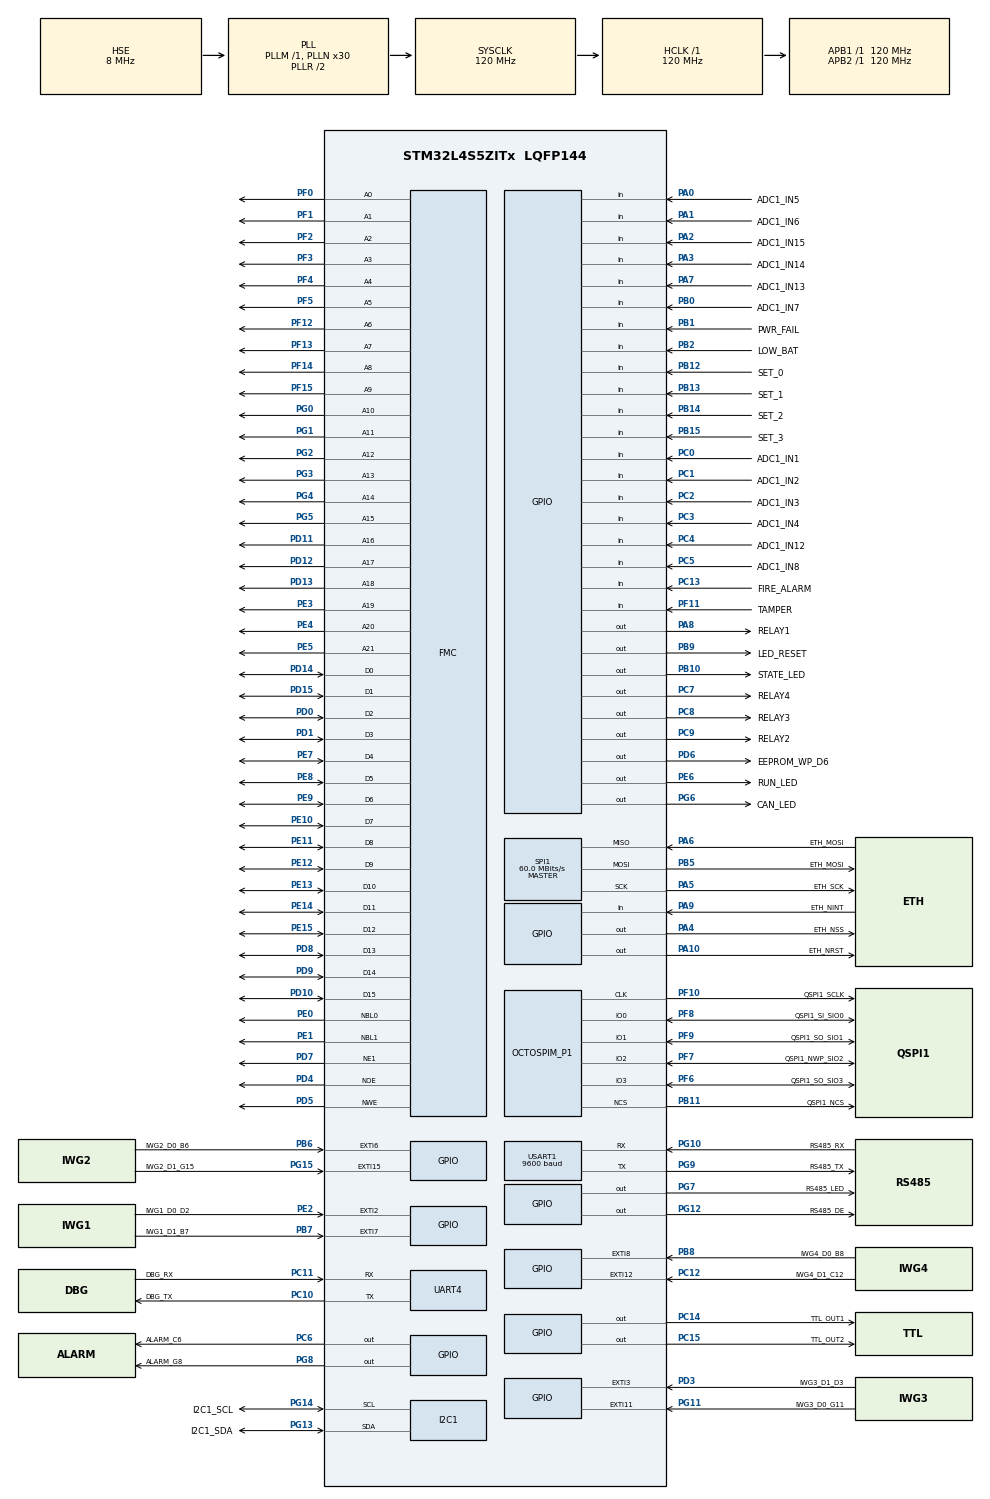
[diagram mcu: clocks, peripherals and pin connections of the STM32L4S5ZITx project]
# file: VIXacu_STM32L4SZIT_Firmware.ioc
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CRC.DefaultInitValueUse=DEFAULT_INIT_VALUE_ENABLE
CRC.DefaultPolynomialUse=DEFAULT_POLYNOMIAL_ENABLE
CRC.InputDataFormat=CRC_INPUTDATA_FORMAT_WORDS
Dma.Request0=SPI1_TX
Dma.Request1=SPI1_RX
Dma.SPI1_RX.1.Direction=DMA_PERIPH_TO_MEMORY
Dma.SPI1_RX.1.EventEnable=DISABLE
Dma.SPI1_RX.1.Instance=DMA1_Channel1
Dma.SPI1_RX.1.MemDataAlignment=DMA_MDATAALIGN_BYTE
Dma.SPI1_RX.1.MemInc=DMA_MINC_ENABLE
Dma.SPI1_RX.1.Mode=DMA_NORMAL
Dma.SPI1_RX.1.PeriphDataAlignment=DMA_PDATAALIGN_BYTE
Dma.SPI1_RX.1.PeriphInc=DMA_PINC_DISABLE
Dma.SPI1_RX.1.Polarity=HAL_DMAMUX_REQUEST_GEN_RISING
Dma.SPI1_RX.1.Priority=DMA_PRIORITY_LOW
Dma.SPI1_RX.1.RequestNumber=1
Dma.SPI1_RX.1.SignalID=NONE
Dma.SPI1_RX.1.SyncEnable=DISABLE
Dma.SPI1_RX.1.SyncPolarity=HAL_DMAMUX_SYNC_NO_EVENT
Dma.SPI1_RX.1.SyncRequestNumber=1
Dma.SPI1_RX.1.SyncSignalID=NONE
Dma.SPI1_TX.0.Direction=DMA_MEMORY_TO_PERIPH
Dma.SPI1_TX.0.EventEnable=DISABLE
Dma.SPI1_TX.0.Instance=DMA1_Channel3
Dma.SPI1_TX.0.MemDataAlignment=DMA_MDATAALIGN_BYTE
Dma.SPI1_TX.0.MemInc=DMA_MINC_ENABLE
Dma.SPI1_TX.0.Mode=DMA_NORMAL
Dma.SPI1_TX.0.PeriphDataAlignment=DMA_PDATAALIGN_BYTE
Dma.SPI1_TX.0.PeriphInc=DMA_PINC_DISABLE
Dma.SPI1_TX.0.Polarity=HAL_DMAMUX_REQUEST_GEN_RISING
Dma.SPI1_TX.0.Priority=DMA_PRIORITY_LOW
Dma.SPI1_TX.0.RequestNumber=1
Dma.SPI1_TX.0.SignalID=NONE
Dma.SPI1_TX.0.SyncEnable=DISABLE
Dma.SPI1_TX.0.SyncPolarity=HAL_DMAMUX_SYNC_NO_EVENT
Dma.SPI1_TX.0.SyncRequestNumber=1
Dma.SPI1_TX.0.SyncSignalID=NONE
HASH.SecureHashAlgorithmType=SHA256
I2C1.Timing=0x30A175AB
IWDG.Prescaler=IWDG_PRESCALER_256
Mcu.Family=STM32L4
Mcu.Name=STM32L4S5ZITx
Mcu.Package=LQFP144
NVIC.DMA1_Channel1_IRQn=true\:0\:0\:false\:false\:true\:false\:true\:true
NVIC.DMA1_Channel3_IRQn=true\:0\:0\:false\:false\:true\:false\:true\:true
NVIC.EXTI15_10_IRQn=true\:0\:0\:false\:false\:true\:true\:true\:true
NVIC.EXTI2_IRQn=true\:0\:0\:false\:false\:true\:true\:true\:true
NVIC.EXTI3_IRQn=true\:0\:0\:false\:false\:true\:true\:true\:true
NVIC.EXTI9_5_IRQn=true\:0\:0\:false\:false\:true\:true\:true\:true
NVIC.HASH_CRS_IRQn=true\:0\:0\:false\:false\:true\:true\:true\:true
NVIC.I2C1_ER_IRQn=true\:0\:0\:false\:false\:true\:true\:true\:true
NVIC.OCTOSPI1_IRQn=true\:0\:0\:false\:false\:true\:true\:true\:true
NVIC.PriorityGroup=NVIC_PRIORITYGROUP_4
NVIC.RNG_IRQn=true\:0\:0\:false\:false\:true\:true\:true\:true
NVIC.SPI1_IRQn=true\:0\:0\:false\:false\:true\:true\:true\:true
NVIC.TIM1_CC_IRQn=true\:0\:0\:false\:false\:true\:true\:true\:true
NVIC.TIM1_UP_TIM16_IRQn=true\:0\:0\:false\:false\:true\:true\:true\:true
NVIC.TIM2_IRQn=true\:0\:0\:false\:false\:true\:true\:true\:true
NVIC.TIM3_IRQn=true\:0\:0\:false\:false\:true\:true\:true\:true
NVIC.TIM4_IRQn=true\:0\:0\:false\:false\:true\:true\:true\:true
NVIC.TIM5_IRQn=true\:0\:0\:false\:false\:true\:true\:true\:true
NVIC.TIM6_DAC_IRQn=true\:15\:0\:false\:false\:true\:true\:true\:true
NVIC.TIM7_IRQn=true\:0\:0\:false\:false\:true\:true\:true\:true
NVIC.UART4_IRQn=true\:15\:0\:true\:false\:true\:true\:true\:true
NVIC.USART1_IRQn=true\:5\:0\:true\:false\:true\:true\:true\:true
OCTOSPI1.ChipSelectHighTime=2
OCTOSPI1.ClockPrescaler=2
OCTOSPI1.DelayBlockBypass=HAL_OSPI_DELAY_BLOCK_BYPASSED
OCTOSPI1.DelayHoldQuarterCycle=HAL_OSPI_DHQC_DISABLE
OCTOSPI1.DeviceSize=26
OCTOSPI1.FifoThreshold=4
OCTOSPI1.MemoryType=HAL_OSPI_MEMTYPE_MACRONIX
OCTOSPI1.SampleShifting=HAL_OSPI_SAMPLE_SHIFTING_HALFCYCLE
PA0.GPIO_Label=ADC1_IN5
PA0.Signal=GPIO_Input
PA1.GPIO_Label=ADC1_IN6
PA1.Signal=GPIO_Input
PA10.GPIO_Label=ETH_NRST
PA10.PinState=GPIO_PIN_SET
PA10.Signal=GPIO_Output
PA13\ (JTMS/SWDIO).Mode=Trace_Asynchronous_SW
PA13\ (JTMS/SWDIO).Signal=SYS_JTMS-SWDIO
PA14\ (JTCK/SWCLK).Mode=Trace_Asynchronous_SW
PA14\ (JTCK/SWCLK).Signal=SYS_JTCK-SWCLK
PA2.GPIO_Label=ADC1_IN15
PA2.Signal=GPIO_Input
PA3.GPIO_Label=ADC1_IN14
PA3.Signal=GPIO_Input
PA4.GPIO_Label=ETH_NSS
PA4.Signal=GPIO_Output
PA5.GPIO_Label=ETH_SCK
PA5.Mode=Full_Duplex_Master
PA5.Signal=SPI1_SCK
PA6.GPIO_Label=ETH_MOSI
PA6.Mode=Full_Duplex_Master
PA6.Signal=SPI1_MISO
PA7.GPIO_Label=ADC1_IN13
PA7.Signal=GPIO_Input
PA8.GPIO_Label=RELAY1
PA8.Signal=GPIO_Output
PA9.GPIO_Label=ETH_NINT
PA9.GPIO_PuPd=GPIO_PULLUP
PA9.Signal=GPIO_Input
PB0.GPIO_Label=ADC1_IN7
PB0.Signal=GPIO_Input
PB1.GPIO_Label=PWR_FAIL
PB1.Signal=GPIO_Input
PB10.GPIO_Label=STATE_LED
PB10.Signal=GPIO_Output
PB11.GPIO_Label=QSPI1_NCS
PB11.Mode=OCTOSPI1_Port1_NCS
PB11.Signal=OCTOSPIM_P1_NCS
PB12.GPIO_Label=SET_0
PB12.Signal=GPIO_Input
PB13.GPIO_Label=SET_1
PB13.Signal=GPIO_Input
PB14.GPIO_Label=SET_2
PB14.Signal=GPIO_Input
PB15.GPIO_Label=SET_3
PB15.Signal=GPIO_Input
PB2.GPIO_Label=LOW_BAT
PB2.Signal=GPIO_Input
PB3\ (JTDO/TRACESWO).Mode=Trace_Asynchronous_SW
PB3\ (JTDO/TRACESWO).Signal=SYS_JTDO-SWO
PB5.GPIO_Label=ETH_MOSI
PB5.Mode=Full_Duplex_Master
PB5.Signal=SPI1_MOSI
PB6.GPIO_Label=IWG2_D0_B6
PB6.GPIO_ModeDefaultEXTI=GPIO_MODE_IT_FALLING
PB6.GPIO_PuPd=GPIO_PULLUP
PB6.Signal=GPXTI6
PB7.GPIO_Label=IWG1_D1_B7
PB7.GPIO_ModeDefaultEXTI=GPIO_MODE_IT_FALLING
PB7.GPIO_PuPd=GPIO_PULLUP
PB7.Signal=GPXTI7
PB8.GPIO_Label=IWG4_D0_B8
PB8.GPIO_ModeDefaultEXTI=GPIO_MODE_IT_FALLING
PB8.GPIO_PuPd=GPIO_PULLUP
PB8.Signal=GPXTI8
PB9.GPIO_Label=LED_RESET
PB9.GPIO_PuPd=GPIO_NOPULL
PB9.PinState=GPIO_PIN_SET
PB9.Signal=GPIO_Output
PC0.GPIO_Label=ADC1_IN1
PC0.Signal=GPIO_Input
PC1.GPIO_Label=ADC1_IN2
PC1.Signal=GPIO_Input
PC10.GPIO_Label=DBG_TX
PC10.Mode=Asynchronous
PC10.Signal=UART4_TX
PC11.GPIO_Label=DBG_RX
PC11.GPIO_PuPd=GPIO_PULLUP
PC11.Mode=Asynchronous
PC11.Signal=UART4_RX
PC12.GPIO_Label=IWG4_D1_C12
PC12.GPIO_ModeDefaultEXTI=GPIO_MODE_IT_FALLING
PC12.GPIO_PuPd=GPIO_PULLUP
PC12.Signal=GPXTI12
PC13.GPIO_Label=FIRE_ALARM
PC13.Signal=GPIO_Input
PC14-OSC32_IN\ (PC14).GPIO_Label=TTL_OUT1
PC14-OSC32_IN\ (PC14).Signal=GPIO_Output
PC15-OSC32_OUT\ (PC15).GPIO_Label=TTL_OUT2
PC15-OSC32_OUT\ (PC15).Signal=GPIO_Output
PC2.GPIO_Label=ADC1_IN3
PC2.Signal=GPIO_Input
PC3.GPIO_Label=ADC1_IN4
PC3.Signal=GPIO_Input
PC4.GPIO_Label=ADC1_IN12
PC4.Signal=GPIO_Input
PC5.GPIO_Label=ADC1_IN8
PC5.Signal=GPIO_Input
PC6.GPIO_Label=ALARM_C6
PC6.Signal=GPIO_Output
PC7.GPIO_Label=RELAY4
PC7.Signal=GPIO_Output
PC8.GPIO_Label=RELAY3
PC8.Signal=GPIO_Output
PC9.GPIO_Label=RELAY2
PC9.Signal=GPIO_Output
PD0.Signal=FMC_D2_DA2
PD1.Signal=FMC_D3_DA3
PD10.Signal=FMC_D15_DA15
PD11.Signal=FMC_A16_CLE
PD12.Signal=FMC_A17_ALE
PD13.Signal=FMC_A18
PD14.Signal=FMC_D0_DA0
PD15.Signal=FMC_D1_DA1
PD3.GPIO_Label=IWG3_D1_D3
PD3.GPIO_ModeDefaultEXTI=GPIO_MODE_IT_FALLING
PD3.GPIO_PuPd=GPIO_PULLUP
PD3.Signal=GPXTI3
PD4.Signal=FMC_NOE
PD5.Signal=FMC_NWE
PD6.GPIO_Label=EEPROM_WP_D6
PD6.GPIO_PuPd=GPIO_PULLDOWN
PD6.Signal=GPIO_Output
PD7.Mode=NorPsramChipSelect1_1
PD7.Signal=FMC_NE1
PD8.Signal=FMC_D13_DA13
PD9.Signal=FMC_D14_DA14
PE0.Signal=FMC_NBL0
PE1.Signal=FMC_NBL1
PE10.Signal=FMC_D7_DA7
PE11.Signal=FMC_D8_DA8
PE12.Signal=FMC_D9_DA9
PE13.Signal=FMC_D10_DA10
PE14.Signal=FMC_D11_DA11
PE15.Signal=FMC_D12_DA12
PE2.GPIO_Label=IWG1_D0_D2
PE2.GPIO_ModeDefaultEXTI=GPIO_MODE_IT_FALLING
PE2.GPIO_PuPd=GPIO_PULLUP
PE2.Signal=GPXTI2
PE3.Signal=FMC_A19
PE4.Signal=FMC_A20
PE5.Signal=FMC_A21
PE6.GPIO_Label=RUN_LED
PE6.Signal=GPIO_Output
PE7.Signal=FMC_D4_DA4
PE8.Signal=FMC_D5_DA5
PE9.Signal=FMC_D6_DA6
PF0.Signal=FMC_A0
PF1.Signal=FMC_A1
PF10.GPIO_Label=QSPI1_SCLK
PF10.Mode=O1_P1_CLK
PF10.Signal=OCTOSPIM_P1_CLK
PF11.GPIO_Label=TAMPER
PF11.Signal=GPIO_Input
PF12.Signal=FMC_A6
PF13.Signal=FMC_A7
PF14.Signal=FMC_A8
PF15.Signal=FMC_A9
PF2.Signal=FMC_A2
PF3.Signal=FMC_A3
PF4.Signal=FMC_A4
PF5.Signal=FMC_A5
PF6.GPIO_Label=QSPI1_SO_SIO3
PF6.Mode=OCTOSPI1_IOL_Port1L
PF6.Signal=OCTOSPIM_P1_IO3
PF7.GPIO_Label=QSPI1_NWP_SIO2
PF7.GPIO_PuPd=GPIO_NOPULL
PF7.Mode=OCTOSPI1_IOL_Port1L
PF7.Signal=OCTOSPIM_P1_IO2
PF8.GPIO_Label=QSPI1_SI_SIO0
PF8.GPIO_PuPd=GPIO_NOPULL
PF8.Mode=OCTOSPI1_IOL_Port1L
PF8.Signal=OCTOSPIM_P1_IO0
PF9.GPIO_Label=QSPI1_SO_SIO1
PF9.Mode=OCTOSPI1_IOL_Port1L
PF9.Signal=OCTOSPIM_P1_IO1
PG0.Signal=FMC_A10
PG1.Signal=FMC_A11
PG10.GPIO_Label=RS485_RX
PG10.Mode=Asynchronous
PG10.Signal=USART1_RX
PG11.GPIO_Label=IWG3_D0_G11
PG11.GPIO_ModeDefaultEXTI=GPIO_MODE_IT_FALLING
PG11.GPIO_PuPd=GPIO_PULLUP
PG11.Signal=GPXTI11
PG12.GPIO_Label=RS485_DE
PG12.Signal=GPIO_Output
PG13.GPIO_Label=I2C1_SDA
PG13.Mode=I2C
PG13.Signal=I2C1_SDA
PG14.GPIO_Label=I2C1_SCL
PG14.Mode=I2C
PG14.Signal=I2C1_SCL
PG15.GPIO_Label=IWG2_D1_G15
PG15.GPIO_ModeDefaultEXTI=GPIO_MODE_IT_FALLING
PG15.GPIO_PuPd=GPIO_PULLUP
PG15.Signal=GPXTI15
PG2.Signal=FMC_A12
PG3.Signal=FMC_A13
PG4.Signal=FMC_A14
PG5.Signal=FMC_A15
PG6.GPIO_Label=CAN_LED
PG6.Signal=GPIO_Output
PG7.GPIO_Label=RS485_LED
PG7.Signal=GPIO_Output
PG8.GPIO_Label=ALARM_G8
PG8.Signal=GPIO_Output
PG9.GPIO_Label=RS485_TX
PG9.Mode=Asynchronous
PG9.Signal=USART1_TX
PH0-OSC_IN\ (PH0).Mode=HSE-External-Oscillator
PH0-OSC_IN\ (PH0).Signal=RCC_OSC_IN
PH1-OSC_OUT\ (PH1).Mode=HSE-External-Oscillator
PH1-OSC_OUT\ (PH1).Signal=RCC_OSC_OUT
ProjectManager.HeapSize=0x4000
ProjectManager.StackSize=0x4000
ProjectManager.TargetToolchain=STM32CubeIDE
RCC.ADCFreq_Value=32000000
RCC.AHBFreq_Value=120000000
RCC.APB1Freq_Value=120000000
RCC.APB1TimFreq_Value=120000000
RCC.APB2Freq_Value=120000000
RCC.APB2TimFreq_Value=120000000
RCC.CortexFreq_Value=120000000
RCC.EnbaleCSS=true
RCC.HCLKFreq_Value=120000000
RCC.HSE_VALUE=8000000
RCC.HSI48_VALUE=48000000
RCC.HSI_VALUE=16000000
RCC.LSE_VALUE=32768
RCC.MSI_VALUE=4000000
RCC.OCTOSPIMCLockSelection=RCC_OSPICLKSOURCE_PLL
RCC.PLLN=30
RCC.PLLSourceVirtual=RCC_PLLSOURCE_HSE
RCC.SYSCLKFreq_VALUE=120000000
RCC.SYSCLKSource=RCC_SYSCLKSOURCE_PLLCLK
RCC.USBFreq_Value=32000000
RCC.VCOOutputFreq_Value=240000000
SH.FMC_A0.0=FMC_A0,22b-a1
SH.FMC_A1.0=FMC_A1,22b-a1
SH.FMC_A10.0=FMC_A10,22b-a1
SH.FMC_A11.0=FMC_A11,22b-a1
SH.FMC_A12.0=FMC_A12,22b-a1
SH.FMC_A13.0=FMC_A13,22b-a1
SH.FMC_A14.0=FMC_A14,22b-a1
SH.FMC_A15.0=FMC_A15,22b-a1
SH.FMC_A16_CLE.0=FMC_A16,22b-a1
SH.FMC_A17_ALE.0=FMC_A17,22b-a1
SH.FMC_A18.0=FMC_A18,22b-a1
SH.FMC_A19.0=FMC_A19,22b-a1
SH.FMC_A2.0=FMC_A2,22b-a1
SH.FMC_A20.0=FMC_A20,22b-a1
SH.FMC_A21.0=FMC_A21,22b-a1
SH.FMC_A3.0=FMC_A3,22b-a1
SH.FMC_A4.0=FMC_A4,22b-a1
SH.FMC_A5.0=FMC_A5,22b-a1
SH.FMC_A6.0=FMC_A6,22b-a1
SH.FMC_A7.0=FMC_A7,22b-a1
SH.FMC_A8.0=FMC_A8,22b-a1
SH.FMC_A9.0=FMC_A9,22b-a1
SH.FMC_D0_DA0.0=FMC_D0,16b-d1
SH.FMC_D10_DA10.0=FMC_D10,16b-d1
SH.FMC_D11_DA11.0=FMC_D11,16b-d1
SH.FMC_D12_DA12.0=FMC_D12,16b-d1
SH.FMC_D13_DA13.0=FMC_D13,16b-d1
SH.FMC_D14_DA14.0=FMC_D14,16b-d1
SH.FMC_D15_DA15.0=FMC_D15,16b-d1
SH.FMC_D1_DA1.0=FMC_D1,16b-d1
SH.FMC_D2_DA2.0=FMC_D2,16b-d1
SH.FMC_D3_DA3.0=FMC_D3,16b-d1
SH.FMC_D4_DA4.0=FMC_D4,16b-d1
SH.FMC_D5_DA5.0=FMC_D5,16b-d1
SH.FMC_D6_DA6.0=FMC_D6,16b-d1
SH.FMC_D7_DA7.0=FMC_D7,16b-d1
SH.FMC_D8_DA8.0=FMC_D8,16b-d1
SH.FMC_D9_DA9.0=FMC_D9,16b-d1
SH.FMC_NBL0.0=FMC_NBL0,2ByteEnable1
SH.FMC_NBL1.0=FMC_NBL1,2ByteEnable1
SH.FMC_NOE.0=FMC_NOE,Psram1
SH.FMC_NWE.0=FMC_NWE,Psram1
SPI1.BaudRatePrescaler=SPI_BAUDRATEPRESCALER_2
SPI1.CLKPhase=SPI_PHASE_2EDGE
SPI1.CLKPolarity=SPI_POLARITY_HIGH
SPI1.CRCCalculation=SPI_CRCCALCULATION_DISABLE
SPI1.CalculateBaudRate=60.0 MBits/s
SPI1.DataSize=SPI_DATASIZE_8BIT
SPI1.Direction=SPI_DIRECTION_2LINES
SPI1.Mode=SPI_MODE_MASTER
SPI1.VirtualType=VM_MASTER
TIM1.AutoReloadPreload=TIM_AUTORELOAD_PRELOAD_ENABLE
TIM1.Period=9999
TIM1.Prescaler=11999
TIM2.AutoReloadPreload=TIM_AUTORELOAD_PRELOAD_ENABLE
TIM2.Period=9999
TIM2.Prescaler=119
TIM3.AutoReloadPreload=TIM_AUTORELOAD_PRELOAD_ENABLE
TIM3.Period=999
TIM3.Prescaler=119
TIM4.AutoReloadPreload=TIM_AUTORELOAD_PRELOAD_ENABLE
TIM4.Period=9999
TIM4.Prescaler=1199
TIM5.AutoReloadPreload=TIM_AUTORELOAD_PRELOAD_ENABLE
TIM5.Period=4999
TIM5.Prescaler=1199
TIM6.AutoReloadPreload=TIM_AUTORELOAD_PRELOAD_ENABLE
TIM6.Period=4999
TIM6.Prescaler=1199
TIM7.AutoReloadPreload=TIM_AUTORELOAD_PRELOAD_ENABLE
TIM7.Period=999
TIM7.Prescaler=119
UART4.ClockPrescaler=PRESCALER_DIV12
USART1.BaudRate=9600
USART1.ClockPrescaler=PRESCALER_DIV12
USART1.VirtualMode-Asynchronous=VM_ASYNC
VP_CRC_VS_CRC.Mode=CRC_Activate
VP_HASH_VS_HASH.Mode=HASH_Activate
VP_IWDG_VS_IWDG.Mode=IWDG_Activate
VP_OCTOSPI1_VS_quad.Mode=quad_mode
VP_RNG_VS_RNG.Mode=RNG_Activate
VP_RTC_VS_RTC_Activate.Mode=RTC_Enabled
VP_TIM1_VS_ClockSourceINT.Mode=Internal
VP_TIM2_VS_ClockSourceINT.Mode=Internal
VP_TIM3_VS_ClockSourceINT.Mode=Internal
VP_TIM4_VS_ClockSourceINT.Mode=Internal
VP_TIM5_VS_ClockSourceINT.Mode=Internal
VP_TIM6_VS_ClockSourceINT.Mode=Enable_Timer
VP_TIM7_VS_ClockSourceINT.Mode=Enable_Timer
board=custom

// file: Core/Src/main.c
/* USER CODE BEGIN Header */
/**
  ******************************************************************************
  * @file           : main.c
  * @brief          : Main program body
  ******************************************************************************
  * @attention
  *
  * Copyright (c) 2024 STMicroelectronics.
  * All rights reserved.
  *
  * This software is licensed under terms that can be found in the LICENSE file
  * in the root directory of this software component.
  * If no LICENSE file comes with this software, it is provided AS-IS.
  *
  ******************************************************************************
  */
/* USER CODE END Header */
#include "main.h"
#include "crc.h"
#include "dma.h"
#include "hash.h"
#include "i2c.h"
#include "iwdg.h"
#include "octospi.h"
#include "rng.h"
#include "rtc.h"
#include "spi.h"
#include "tim.h"
#include "usart.h"
#include "gpio.h"
#include "fmc.h"

/* USER CODE BEGIN Includes */
#include "vixConfig.h"

/* USER CODE END Includes */

/* USER CODE BEGIN PM */
extern uint32_t delay_ticks;

void MyMsDelay(uint32_t milisecons)
{
	delay_ticks = milisecons;
	while ( delay_ticks > 0) {
		// CPU ?��?�� ?��?�� ??�???
	}
}

void MyUsDelay(uint32_t microseconds)
{
  /* Go to number of cycles for system */
  microseconds *= (SystemCoreClock / 1000000);
  /* Delay till end */
  while (microseconds--);
}

/* USER CODE END PM */

/* USER CODE BEGIN PV */
/*
static OS_STACKPTR			int Stack0[128];
static OS_TASK				TCB0;
*/

/* USER CODE END PV */

void SystemClock_Config(void);

int main(void)
{

  /* MCU Configuration--------------------------------------------------------*/

  /* Reset of all peripherals, Initializes the Flash interface and the Systick. */
  HAL_Init();

  /* Configure the system clock */
  SystemClock_Config();

  /* Initialize all configured peripherals */
  MX_GPIO_Init();
  MX_DMA_Init();
  MX_FMC_Init();
  MX_I2C1_Init();
  MX_OCTOSPI1_Init();
  MX_UART4_Init();
  MX_USART1_UART_Init();
  MX_SPI1_Init();
  MX_CRC_Init();
  MX_HASH_Init();
  MX_RNG_Init();
  MX_TIM6_Init();
#ifndef DEBUG_MODE
  MX_IWDG_Init();
#endif
  MX_TIM3_Init();
  MX_TIM2_Init();
  MX_TIM4_Init();
  MX_RTC_Init();
  MX_TIM1_Init();
  MX_TIM5_Init();
  MX_TIM7_Init();
  /* USER CODE BEGIN 2 */
  //MX_ADC1_Init();

  HAL_TIM_Base_Start_IT(&htim7);  // �????�� ?���??? ???���??? 초기 ?��?��

  fOpenEthernet = 0;
  //CREATE_DebugConsoleMutex();

  //printf("printf: VIXacu\r\n");
  //Dprintf("VIXacu\r\n");

  OPEN_DebugConsole();
  OPEN_ExNorFlash();
  //OPEN_ArrayLED();
  //xOpen_EepromMutex();

#ifdef DEBUG_MODE
   // TEST_Eeprom();
//   TEST_ExNorFlash();
   // TestLockOut();
   //TEST_RNG();
   //TEST_ExRTC();
   //TEST_LedDriver();
   //TEST_CRC32();
   //TEST_TTLOut(_TTL_OUT);
#endif

   RTC_Initial();
   RS485_Init();
   InputInit();
   SCI1FwdTaskInit();
   PCALED_Init();
   QUEUE_Init_Ring_Queues();

   SystemTask();	// ?�� ?��?���??????? ?��?�� 값을 ?��?�� ?���??????? ?��?��?�� ?��?��.

   Wiegand_init_value();
   SerialProcInit();

   EthernetCommunication();
   OPEN_Ethernet();

   initTaskRunStatus();
  /* USER CODE END 2 */

  /* Infinite loop */
  /* USER CODE BEGIN WHILE */
//   xOSPI_EraseChip();
#ifdef DEBUG_MODE
//   ATE_Test_SetTime();
  //  TEST_ExNorFlash();
//  ATE_Test_AddAuth();
//    ATE_Test_VixpassSchedule();
//  ATE_Test_DoorSync();
//   cB84B3C
 //  B798753C

	uint8_t wiegand[4];   // 4462d901
	wiegand[0] = 0x97; wiegand[1] = 0x84; wiegand[2] = 0x4B; wiegand[3] = 0x3C;
	ATE_Test_ID(wiegand);
	/*
	 * 	wiegand[0] = 0xD5; wiegand[1] = 0x84; wiegand[2] = 0xA1; wiegand[3] = 0x9A;
	ATE_Test_ID(wiegand);
	wiegand[0] = 0x00; wiegand[1] = 0x49; wiegand[2] = 0x12; wiegand[3] = 0x7C;
	ATE_Test_ID(wiegand);
	wiegand[0] = 0x7C; wiegand[1] = 0x0C; wiegand[2] = 0x12; wiegand[3] = 0x7C;
	ATE_Test_ID(wiegand);
	wiegand[0] = 0x00; wiegand[1] = 0x18; wiegand[2] = 0x12; wiegand[3] = 0x7B;
	ATE_Test_ID(wiegand);
*/
#endif

	while (1)
	{
		SerialCommandProcess();

#ifdef GUUI_PULLMAN_485
		SCI2Rs485Process();
#endif
#ifdef KTWEST_WIEGAND
		WiegandProcess();
#endif
		SPI1NetTask();
		InProcess();

	/* USER CODE END WHILE */

	/* USER CODE BEGIN 3 */
		HAL_IWDG_Refresh(&hiwdg);
	//	  HAL_Delay(10);
	}
	/* USER CODE END 3 */
}

void SystemClock_Config(void)
{
  RCC_OscInitTypeDef RCC_OscInitStruct = {0};
  RCC_ClkInitTypeDef RCC_ClkInitStruct = {0};

  /** Configure the main internal regulator output voltage
  */
  if (HAL_PWREx_ControlVoltageScaling(PWR_REGULATOR_VOLTAGE_SCALE1_BOOST) != HAL_OK)
  {
    Error_Handler();
  }

  /** Initializes the RCC Oscillators according to the specified parameters
  * in the RCC_OscInitTypeDef structure.
  */
  RCC_OscInitStruct.OscillatorType = RCC_OSCILLATORTYPE_LSI|RCC_OSCILLATORTYPE_HSE;
  RCC_OscInitStruct.HSEState = RCC_HSE_ON;
  RCC_OscInitStruct.LSIState = RCC_LSI_ON;
  RCC_OscInitStruct.PLL.PLLState = RCC_PLL_ON;
  RCC_OscInitStruct.PLL.PLLSource = RCC_PLLSOURCE_HSE;
  RCC_OscInitStruct.PLL.PLLM = 1;
  RCC_OscInitStruct.PLL.PLLN = 30;
  RCC_OscInitStruct.PLL.PLLP = RCC_PLLP_DIV2;
  RCC_OscInitStruct.PLL.PLLQ = RCC_PLLQ_DIV2;
  RCC_OscInitStruct.PLL.PLLR = RCC_PLLR_DIV2;
  if (HAL_RCC_OscConfig(&RCC_OscInitStruct) != HAL_OK)
  {
    Error_Handler();
  }

  /** Initializes the CPU, AHB and APB buses clocks
  */
  RCC_ClkInitStruct.ClockType = RCC_CLOCKTYPE_HCLK|RCC_CLOCKTYPE_SYSCLK
                              |RCC_CLOCKTYPE_PCLK1|RCC_CLOCKTYPE_PCLK2;
  RCC_ClkInitStruct.SYSCLKSource = RCC_SYSCLKSOURCE_PLLCLK;
  RCC_ClkInitStruct.AHBCLKDivider = RCC_SYSCLK_DIV1;
  RCC_ClkInitStruct.APB1CLKDivider = RCC_HCLK_DIV1;
  RCC_ClkInitStruct.APB2CLKDivider = RCC_HCLK_DIV1;

  if (HAL_RCC_ClockConfig(&RCC_ClkInitStruct, FLASH_LATENCY_5) != HAL_OK)
  {
    Error_Handler();
  }

  /** Enables the Clock Security System
  */
  HAL_RCC_EnableCSS();
}

/* USER CODE BEGIN 4 */
//while(HAL_I2C_Master_Transmit(&hi2c1, addr, &data, 1, 100000) != HAL_OK);

/* USER CODE END 4 */

void Error_Handler(void)
{
  __disable_irq();
  while (1)
  {
  }
}
